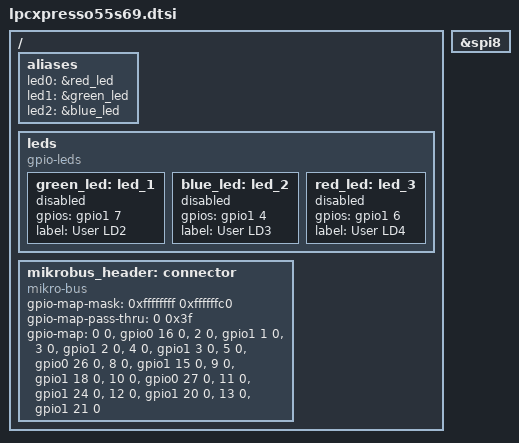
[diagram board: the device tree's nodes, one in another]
/*
 * Copyright (c) 2019, NXP
 *
 * SPDX-License-Identifier: Apache-2.0
 */

/ {
	aliases{
		led0 = &red_led;
		led1 = &green_led;
		led2 = &blue_led;
	};

	leds {
		compatible = "gpio-leds";
		green_led: led_1 {
			gpios = <&gpio1 7 0>;
			label = "User LD2";
			status = "disabled";
		};
		blue_led: led_2 {
			gpios = <&gpio1 4 0>;
			label = "User LD3";
			status = "disabled";
		};
		red_led: led_3 {
			gpios = <&gpio1 6 0>;
			label = "User LD4";
			status = "disabled";
		};
	};

	// TODO: actualy map these
	// arduino_header: connector {
	// 	compatible = "arduino-header-r3";
	// 	#gpio-cells = <2>;
	// 	gpio-map-mask = <0xffffffff 0xffffffc0>;
	// 	gpio-map-pass-thru = <0 0x3f>;
	// 	gpio-map = <0 0 &gpiob 2 0>,	/* A0 */
	// 			<1 0 &gpiob 3 0>,	/* A1 */
	// 			<2 0 &gpiob 10 0>,	/* A2 */
	// 			<3 0 &gpiob 11 0>,	/* A3 */
	// 			<4 0 &gpioc 11 0>,	/* A4 */
	// 			<5 0 &gpioc 10 0>,	/* A5 */
	// 			<6 0 &gpioc 16 0>,	/* D0 */
	// 			<7 0 &gpioc 17 0>,	/* D1 */
	// 			<8 0 &gpiob 9 0>,	/* D2 */
	// 			<9 0 &gpioa 1 0>,	/* D3 */
	// 			<10 0 &gpiob 23 0>,	/* D4 */
	// 			<11 0 &gpioa 2 0>,	/* D5 */
	// 			<12 0 &gpioc 2 0>,	/* D6 */
	// 			<13 0 &gpioc 3 0>,	/* D7 */
	// 			/* NOTE: HW Rev D and below use: */
	// 			/* <14 0 &gpioa 0 0>, */
	// 			/* NOTE: HW Rev E and on use: */
	// 			<14 0 &gpioc 12 0>,	/* D8 */
	// 			<15 0 &gpioc 4 0>,	/* D9 */
	// 			<16 0 &gpiod 0 0>,	/* D10 */
	// 			<17 0 &gpiod 2 0>,	/* D11 */
	// 			<18 0 &gpiod 3 0>,	/* D12 */
	// 			<19 0 &gpiod 1 0>,	/* D13 */
	// 			<20 0 &gpioe 25 0>,	/* D14 */
	// 			<21 0 &gpioe 24 0>;	/* D15 */
	// };

	mikrobus_header: connector {
		compatible = "mikro-bus";
		#gpio-cells = <2>;
		gpio-map-mask = <0xffffffff 0xffffffc0>;
		gpio-map-pass-thru = <0 0x3f>;
		gpio-map = <0 0 &gpio0 16 0>, /* AN  */
				/* RST */
				<2 0 &gpio1 1 0>,	/* CS   */
				<3 0 &gpio1 2 0>,	/* SCK  */
				<4 0 &gpio1 3 0>,	/* MISO */
				<5 0 &gpio0 26 0>,	/* MOSI */
				/* +3.3V */
				/* GND */
				<8 0 &gpio1 15 0>,	/* PWM  */
				<9 0 &gpio1 18 0>,	/* INT  */
				<10 0 &gpio0 27 0>,	/* RX   */
				<11 0 &gpio1 24 0>,	/* TX   */
				<12 0 &gpio1 20 0>,	/* SCL  */
				<13 0 &gpio1 21 0>;	/* SDA  */
				/* +5V */
				/* GND */
	};
};

arduino_spi: &spi8 {};
